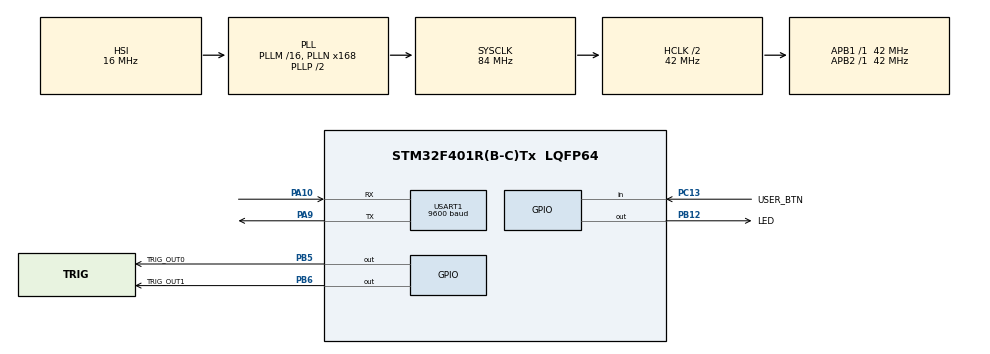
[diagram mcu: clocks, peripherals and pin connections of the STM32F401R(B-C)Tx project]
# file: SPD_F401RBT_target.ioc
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Dma.Request0=USART1_RX
Dma.Request1=USART1_TX
Dma.USART1_RX.0.Direction=DMA_PERIPH_TO_MEMORY
Dma.USART1_RX.0.FIFOMode=DMA_FIFOMODE_ENABLE
Dma.USART1_RX.0.FIFOThreshold=DMA_FIFO_THRESHOLD_FULL
Dma.USART1_RX.0.Instance=DMA2_Stream2
Dma.USART1_RX.0.MemBurst=DMA_MBURST_SINGLE
Dma.USART1_RX.0.MemDataAlignment=DMA_MDATAALIGN_BYTE
Dma.USART1_RX.0.MemInc=DMA_MINC_ENABLE
Dma.USART1_RX.0.Mode=DMA_NORMAL
Dma.USART1_RX.0.PeriphBurst=DMA_PBURST_SINGLE
Dma.USART1_RX.0.PeriphDataAlignment=DMA_PDATAALIGN_BYTE
Dma.USART1_RX.0.PeriphInc=DMA_PINC_DISABLE
Dma.USART1_RX.0.Priority=DMA_PRIORITY_LOW
Dma.USART1_TX.1.Direction=DMA_MEMORY_TO_PERIPH
Dma.USART1_TX.1.FIFOMode=DMA_FIFOMODE_DISABLE
Dma.USART1_TX.1.Instance=DMA2_Stream7
Dma.USART1_TX.1.MemDataAlignment=DMA_MDATAALIGN_BYTE
Dma.USART1_TX.1.MemInc=DMA_MINC_ENABLE
Dma.USART1_TX.1.Mode=DMA_NORMAL
Dma.USART1_TX.1.PeriphDataAlignment=DMA_PDATAALIGN_BYTE
Dma.USART1_TX.1.PeriphInc=DMA_PINC_DISABLE
Dma.USART1_TX.1.Priority=DMA_PRIORITY_LOW
Mcu.Family=STM32F4
Mcu.Name=STM32F401R(B-C)Tx
Mcu.Package=LQFP64
NVIC.DMA2_Stream2_IRQn=true\:0\:0\:false\:false\:true\:false\:true\:true
NVIC.DMA2_Stream7_IRQn=true\:0\:0\:false\:false\:true\:false\:true\:true
NVIC.PriorityGroup=NVIC_PRIORITYGROUP_4
NVIC.TIM3_IRQn=true\:0\:0\:false\:false\:true\:true\:true\:true
NVIC.USART1_IRQn=true\:0\:0\:false\:false\:true\:true\:true\:true
PA10.Mode=Asynchronous
PA10.Signal=USART1_RX
PA9.Mode=Asynchronous
PA9.Signal=USART1_TX
PB12.GPIO_Label=LED
PB12.Signal=GPIO_Output
PB5.GPIO_Label=TRIG_OUT0
PB5.Signal=GPIO_Output
PB6.GPIO_Label=TRIG_OUT1
PB6.Signal=GPIO_Output
PC13-ANTI_TAMP.GPIO_Label=USER_BTN
PC13-ANTI_TAMP.Signal=GPIO_Input
ProjectManager.HeapSize=0x200
ProjectManager.StackSize=0x400
ProjectManager.TargetToolchain=STM32CubeIDE
RCC.48MHZClocksFreq_Value=42000000
RCC.AHBCLKDivider=RCC_SYSCLK_DIV2
RCC.AHBFreq_Value=42000000
RCC.APB1Freq_Value=42000000
RCC.APB1TimFreq_Value=42000000
RCC.APB2Freq_Value=42000000
RCC.APB2TimFreq_Value=42000000
RCC.CortexFreq_Value=42000000
RCC.HCLKFreq_Value=42000000
RCC.HSE_VALUE=25000000
RCC.HSI_VALUE=16000000
RCC.LSE_VALUE=32768
RCC.PLLN=168
RCC.SYSCLKFreq_VALUE=84000000
RCC.SYSCLKSource=RCC_SYSCLKSOURCE_PLLCLK
RCC.VCOOutputFreq_Value=168000000
TIM3.AutoReloadPreload=TIM_AUTORELOAD_PRELOAD_ENABLE
TIM3.Period=10
TIM3.Prescaler=15999
USART1.BaudRate=9600
USART1.VirtualMode=VM_ASYNC
VP_TIM3_VS_ClockSourceINT.Mode=Internal
board=custom

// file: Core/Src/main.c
/* USER CODE BEGIN Header */
/**
  ******************************************************************************
  * @file           : main.c
  * @brief          : Main program body
  ******************************************************************************
  * @attention
  *
  * Copyright (c) 2023 STMicroelectronics.
  * All rights reserved.
  *
  * This software is licensed under terms that can be found in the LICENSE file
  * in the root directory of this software component.
  * If no LICENSE file comes with this software, it is provided AS-IS.
  *
  ******************************************************************************
  */
/* USER CODE END Header */
#include "main.h"

TIM_HandleTypeDef htim3;

UART_HandleTypeDef huart1;
DMA_HandleTypeDef hdma_usart1_rx;
DMA_HandleTypeDef hdma_usart1_tx;

void SystemClock_Config(void);
static void MX_GPIO_Init(void);
static void MX_DMA_Init(void);
static void MX_TIM3_Init(void);
static void MX_USART1_UART_Init(void);

int main(void)
{

  /* MCU Configuration--------------------------------------------------------*/

  /* Reset of all peripherals, Initializes the Flash interface and the Systick. */
  HAL_Init();

  /* Configure the system clock */
  SystemClock_Config();

  /* Initialize all configured peripherals */
  MX_GPIO_Init();
  MX_DMA_Init();
  MX_TIM3_Init();
  MX_USART1_UART_Init();
  /* USER CODE BEGIN 2 */
  Init_Cmd_Handling(&htim3, &huart1, &hdma_usart1_tx); // Just associate the correct pointers to local ones

  Start_Cmd_Reception();
  /* USER CODE END 2 */

  /* Infinite loop */
  while (1)
  {

    /* USER CODE BEGIN 3 */
    // Have the CPU Write in registers as much as possible for photoemission imaging
    // Arm Cortex M4 : 3 stage pipeline
    //__asm("NOP");
    //ASM_TRIGGER_HIGH();
    //ASM_TRIGGER_LOW();

    //__WFI();
  }
  /* USER CODE END 3 */
}

void SystemClock_Config(void)
{
  RCC_OscInitTypeDef RCC_OscInitStruct = {0};
  RCC_ClkInitTypeDef RCC_ClkInitStruct = {0};

  /** Configure the main internal regulator output voltage
  */
  __HAL_RCC_PWR_CLK_ENABLE();
  __HAL_PWR_VOLTAGESCALING_CONFIG(PWR_REGULATOR_VOLTAGE_SCALE2);

  /** Initializes the RCC Oscillators according to the specified parameters
  * in the RCC_OscInitTypeDef structure.
  */
  RCC_OscInitStruct.OscillatorType = RCC_OSCILLATORTYPE_HSI;
  RCC_OscInitStruct.HSIState = RCC_HSI_ON;
  RCC_OscInitStruct.HSICalibrationValue = RCC_HSICALIBRATION_DEFAULT;
  RCC_OscInitStruct.PLL.PLLState = RCC_PLL_ON;
  RCC_OscInitStruct.PLL.PLLSource = RCC_PLLSOURCE_HSI;
  RCC_OscInitStruct.PLL.PLLM = 16;
  RCC_OscInitStruct.PLL.PLLN = 168;
  RCC_OscInitStruct.PLL.PLLP = RCC_PLLP_DIV2;
  RCC_OscInitStruct.PLL.PLLQ = 4;
  if (HAL_RCC_OscConfig(&RCC_OscInitStruct) != HAL_OK)
  {
    Error_Handler();
  }

  /** Initializes the CPU, AHB and APB buses clocks
  */
  RCC_ClkInitStruct.ClockType = RCC_CLOCKTYPE_HCLK|RCC_CLOCKTYPE_SYSCLK
                              |RCC_CLOCKTYPE_PCLK1|RCC_CLOCKTYPE_PCLK2;
  RCC_ClkInitStruct.SYSCLKSource = RCC_SYSCLKSOURCE_PLLCLK;
  RCC_ClkInitStruct.AHBCLKDivider = RCC_SYSCLK_DIV2;
  RCC_ClkInitStruct.APB1CLKDivider = RCC_HCLK_DIV1;
  RCC_ClkInitStruct.APB2CLKDivider = RCC_HCLK_DIV1;

  if (HAL_RCC_ClockConfig(&RCC_ClkInitStruct, FLASH_LATENCY_1) != HAL_OK)
  {
    Error_Handler();
  }
}

static void MX_TIM3_Init(void)
{

  TIM_ClockConfigTypeDef sClockSourceConfig = {0};
  TIM_MasterConfigTypeDef sMasterConfig = {0};

  htim3.Instance = TIM3;
  htim3.Init.Prescaler = 15999;
  htim3.Init.CounterMode = TIM_COUNTERMODE_UP;
  htim3.Init.Period = 10;
  htim3.Init.ClockDivision = TIM_CLOCKDIVISION_DIV1;
  htim3.Init.AutoReloadPreload = TIM_AUTORELOAD_PRELOAD_ENABLE;
  if (HAL_TIM_Base_Init(&htim3) != HAL_OK)
  {
    Error_Handler();
  }
  sClockSourceConfig.ClockSource = TIM_CLOCKSOURCE_INTERNAL;
  if (HAL_TIM_ConfigClockSource(&htim3, &sClockSourceConfig) != HAL_OK)
  {
    Error_Handler();
  }
  sMasterConfig.MasterOutputTrigger = TIM_TRGO_RESET;
  sMasterConfig.MasterSlaveMode = TIM_MASTERSLAVEMODE_DISABLE;
  if (HAL_TIMEx_MasterConfigSynchronization(&htim3, &sMasterConfig) != HAL_OK)
  {
    Error_Handler();
  }

}

static void MX_USART1_UART_Init(void)
{

  huart1.Instance = USART1;
  huart1.Init.BaudRate = 9600;
  huart1.Init.WordLength = UART_WORDLENGTH_8B;
  huart1.Init.StopBits = UART_STOPBITS_1;
  huart1.Init.Parity = UART_PARITY_NONE;
  huart1.Init.Mode = UART_MODE_TX_RX;
  huart1.Init.HwFlowCtl = UART_HWCONTROL_NONE;
  huart1.Init.OverSampling = UART_OVERSAMPLING_16;
  if (HAL_UART_Init(&huart1) != HAL_OK)
  {
    Error_Handler();
  }

}

static void MX_DMA_Init(void)
{

  /* DMA controller clock enable */
  __HAL_RCC_DMA2_CLK_ENABLE();

  /* DMA interrupt init */
  /* DMA2_Stream2_IRQn interrupt configuration */
  HAL_NVIC_SetPriority(DMA2_Stream2_IRQn, 0, 0);
  HAL_NVIC_EnableIRQ(DMA2_Stream2_IRQn);
  /* DMA2_Stream7_IRQn interrupt configuration */
  HAL_NVIC_SetPriority(DMA2_Stream7_IRQn, 0, 0);
  HAL_NVIC_EnableIRQ(DMA2_Stream7_IRQn);

}

static void MX_GPIO_Init(void)
{
  GPIO_InitTypeDef GPIO_InitStruct = {0};

  /* GPIO Ports Clock Enable */
  __HAL_RCC_GPIOC_CLK_ENABLE();
  __HAL_RCC_GPIOB_CLK_ENABLE();
  __HAL_RCC_GPIOA_CLK_ENABLE();

  /*Configure GPIO pin Output Level */
  HAL_GPIO_WritePin(GPIOB, LED_Pin|TRIG_OUT0_Pin|TRIG_OUT1_Pin, GPIO_PIN_RESET);

  /*Configure GPIO pin : USER_BTN_Pin */
  GPIO_InitStruct.Pin = USER_BTN_Pin;
  GPIO_InitStruct.Mode = GPIO_MODE_INPUT;
  GPIO_InitStruct.Pull = GPIO_NOPULL;
  HAL_GPIO_Init(USER_BTN_GPIO_Port, &GPIO_InitStruct);

  /*Configure GPIO pins : LED_Pin TRIG_OUT0_Pin TRIG_OUT1_Pin */
  GPIO_InitStruct.Pin = LED_Pin|TRIG_OUT0_Pin|TRIG_OUT1_Pin;
  GPIO_InitStruct.Mode = GPIO_MODE_OUTPUT_PP;
  GPIO_InitStruct.Pull = GPIO_NOPULL;
  GPIO_InitStruct.Speed = GPIO_SPEED_FREQ_LOW;
  HAL_GPIO_Init(GPIOB, &GPIO_InitStruct);

}

void Error_Handler(void)
{
  __disable_irq();
  while (1)
  {
  }
}
